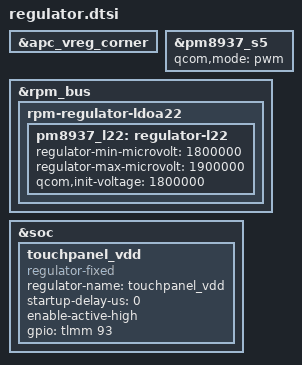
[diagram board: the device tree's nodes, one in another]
&apc_vreg_corner {
	/delete-property/ qcom,cpr-enable;
};

&pm8937_s5 {
	qcom,mode = "pwm";
};

&rpm_bus {
	rpm-regulator-ldoa22 {
		pm8937_l22: regulator-l22 {
			regulator-min-microvolt = <1800000>;
			regulator-max-microvolt = <1900000>;
			qcom,init-voltage = <1800000>;
		};
	};
};

&soc {
	touchpanel_vdd: touchpanel_vdd {
		compatible = "regulator-fixed";
		regulator-name = "touchpanel_vdd";
		startup-delay-us = <0>;
		enable-active-high;
		gpio = <&tlmm 93 0>;
	};

	/delete-node/ adv_vreg;
};
